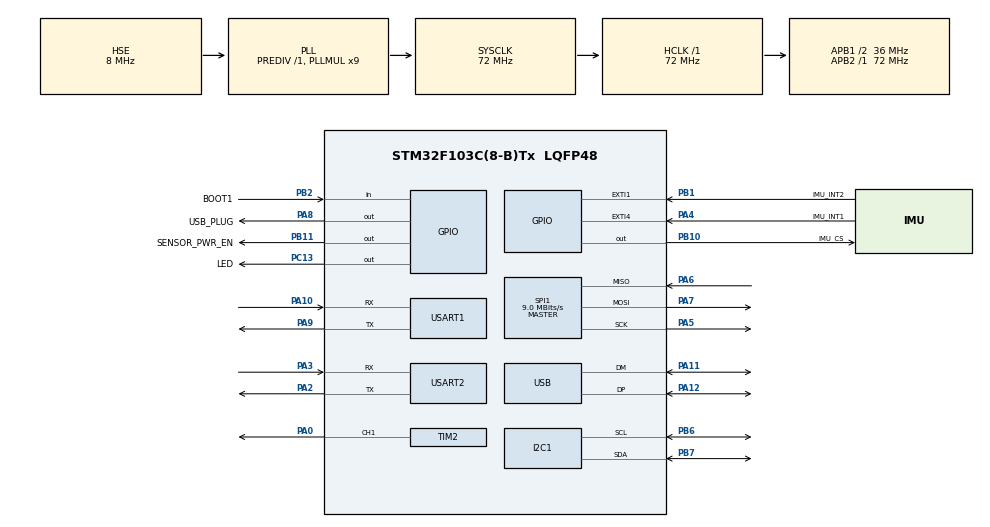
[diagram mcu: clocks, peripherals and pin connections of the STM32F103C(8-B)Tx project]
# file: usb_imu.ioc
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Mcu.Family=STM32F1
Mcu.Name=STM32F103C(8-B)Tx
Mcu.Package=LQFP48
NVIC.PriorityGroup=NVIC_PRIORITYGROUP_4
NVIC.TIM4_IRQn=true\:15\:0\:false\:false\:true\:false\:true\:true
NVIC.TimeBase=TIM4_IRQn
NVIC.TimeBaseIP=TIM4
NVIC.USB_LP_CAN1_RX0_IRQn=true\:0\:0\:false\:false\:true\:false\:true\:true
PA0-WKUP.Signal=S_TIM2_CH1_ETR
PA10.Mode=Asynchronous
PA10.Signal=USART1_RX
PA11.Mode=Device
PA11.Signal=USB_DM
PA12.Mode=Device
PA12.Signal=USB_DP
PA13.Mode=Serial_Wire
PA13.Signal=SYS_JTMS-SWDIO
PA14.Mode=Serial_Wire
PA14.Signal=SYS_JTCK-SWCLK
PA2.Mode=Asynchronous
PA2.Signal=USART2_TX
PA3.Mode=Asynchronous
PA3.Signal=USART2_RX
PA4.GPIO_Label=IMU_INT1
PA4.Signal=GPXTI4
PA5.Mode=Full_Duplex_Master
PA5.Signal=SPI1_SCK
PA6.Mode=Full_Duplex_Master
PA6.Signal=SPI1_MISO
PA7.Mode=Full_Duplex_Master
PA7.Signal=SPI1_MOSI
PA8.GPIO_Label=USB_PLUG
PA8.Signal=GPIO_Output
PA9.Mode=Asynchronous
PA9.Signal=USART1_TX
PB1.GPIO_Label=IMU_INT2
PB1.Signal=GPXTI1
PB10.GPIO_Label=IMU_CS
PB10.Signal=GPIO_Output
PB11.GPIO_Label=SENSOR_PWR_EN
PB11.Signal=GPIO_Output
PB2.GPIO_Label=BOOT1
PB2.Signal=GPIO_Input
PB6.Mode=I2C
PB6.Signal=I2C1_SCL
PB7.Mode=I2C
PB7.Signal=I2C1_SDA
PC13-TAMPER-RTC.GPIO_Label=LED
PC13-TAMPER-RTC.Signal=GPIO_Output
PD0-OSC_IN.Mode=HSE-External-Oscillator
PD0-OSC_IN.Signal=RCC_OSC_IN
PD1-OSC_OUT.Mode=HSE-External-Oscillator
PD1-OSC_OUT.Signal=RCC_OSC_OUT
ProjectManager.HeapSize=0x200
ProjectManager.StackSize=0x400
ProjectManager.TargetToolchain=Makefile
RCC.AHBFreq_Value=72000000
RCC.APB1CLKDivider=RCC_HCLK_DIV2
RCC.APB1Freq_Value=36000000
RCC.APB1TimFreq_Value=72000000
RCC.APB2Freq_Value=72000000
RCC.APB2TimFreq_Value=72000000
RCC.HCLKFreq_Value=72000000
RCC.PLLMUL=RCC_PLL_MUL9
RCC.SYSCLKFreq_VALUE=72000000
RCC.SYSCLKSource=RCC_SYSCLKSOURCE_PLLCLK
RCC.USBFreq_Value=48000000
RCC.USBPrescaler=RCC_USBCLKSOURCE_PLL_DIV1_5
SH.S_TIM2_CH1_ETR.0=TIM2_CH1,PWM Generation1 CH1
SPI1.BaudRatePrescaler=SPI_BAUDRATEPRESCALER_8
SPI1.CalculateBaudRate=9.0 MBits/s
SPI1.Direction=SPI_DIRECTION_2LINES
SPI1.Mode=SPI_MODE_MASTER
SPI1.VirtualType=VM_MASTER
TIM2.Channel-PWM\ Generation1\ CH1=TIM_CHANNEL_1
USART1.VirtualMode=VM_ASYNC
USART2.VirtualMode=VM_ASYNC
USB_DEVICE.CLASS_NAME_FS=CDC
USB_DEVICE.VirtualMode=Cdc
USB_DEVICE.VirtualModeFS=Cdc_FS
VP_CRC_VS_CRC.Mode=CRC_Activate
VP_SYS_VS_tim4.Mode=TIM4
VP_TIM2_VS_ClockSourceINT.Mode=Internal
VP_USB_DEVICE_VS_USB_DEVICE_CDC_FS.Mode=CDC_FS
board=custom

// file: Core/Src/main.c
/* USER CODE BEGIN Header */
/**
  ******************************************************************************
  * @file           : main.c
  * @brief          : Main program body
  ******************************************************************************
  * @attention
  *
  * Copyright (c) 2025 STMicroelectronics.
  * All rights reserved.
  *
  * This software is licensed under terms that can be found in the LICENSE file
  * in the root directory of this software component.
  * If no LICENSE file comes with this software, it is provided AS-IS.
  *
  ******************************************************************************
  */
/* USER CODE END Header */
#include "main.h"
#include "crc.h"
#include "i2c.h"
#include "spi.h"
#include "tim.h"
#include "usart.h"
#include "usb_device.h"
#include "gpio.h"

/* USER CODE BEGIN Includes */
#include "cpp_entry.hpp"
/* USER CODE END Includes */

void SystemClock_Config(void);

int main(void)
{

  /* MCU Configuration--------------------------------------------------------*/

  /* Reset of all peripherals, Initializes the Flash interface and the Systick. */
  HAL_Init();

  /* Configure the system clock */
  SystemClock_Config();

  /* Initialize all configured peripherals */
  MX_GPIO_Init();
  MX_CRC_Init();
  MX_USB_DEVICE_Init();
  MX_I2C1_Init();
  MX_SPI1_Init();
  MX_TIM2_Init();
  MX_USART1_UART_Init();
  MX_USART2_UART_Init();
  /* USER CODE BEGIN 2 */
  setup();
  loop();
  /* USER CODE END 2 */

  /* Infinite loop */
  while (1)
  {

  }
}

void SystemClock_Config(void)
{
  RCC_OscInitTypeDef RCC_OscInitStruct = {0};
  RCC_ClkInitTypeDef RCC_ClkInitStruct = {0};
  RCC_PeriphCLKInitTypeDef PeriphClkInit = {0};

  /** Initializes the RCC Oscillators according to the specified parameters
  * in the RCC_OscInitTypeDef structure.
  */
  RCC_OscInitStruct.OscillatorType = RCC_OSCILLATORTYPE_HSE;
  RCC_OscInitStruct.HSEState = RCC_HSE_ON;
  RCC_OscInitStruct.HSEPredivValue = RCC_HSE_PREDIV_DIV1;
  RCC_OscInitStruct.HSIState = RCC_HSI_ON;
  RCC_OscInitStruct.PLL.PLLState = RCC_PLL_ON;
  RCC_OscInitStruct.PLL.PLLSource = RCC_PLLSOURCE_HSE;
  RCC_OscInitStruct.PLL.PLLMUL = RCC_PLL_MUL9;
  if (HAL_RCC_OscConfig(&RCC_OscInitStruct) != HAL_OK)
  {
    Error_Handler();
  }

  /** Initializes the CPU, AHB and APB buses clocks
  */
  RCC_ClkInitStruct.ClockType = RCC_CLOCKTYPE_HCLK|RCC_CLOCKTYPE_SYSCLK
                              |RCC_CLOCKTYPE_PCLK1|RCC_CLOCKTYPE_PCLK2;
  RCC_ClkInitStruct.SYSCLKSource = RCC_SYSCLKSOURCE_PLLCLK;
  RCC_ClkInitStruct.AHBCLKDivider = RCC_SYSCLK_DIV1;
  RCC_ClkInitStruct.APB1CLKDivider = RCC_HCLK_DIV2;
  RCC_ClkInitStruct.APB2CLKDivider = RCC_HCLK_DIV1;

  if (HAL_RCC_ClockConfig(&RCC_ClkInitStruct, FLASH_LATENCY_2) != HAL_OK)
  {
    Error_Handler();
  }
  PeriphClkInit.PeriphClockSelection = RCC_PERIPHCLK_USB;
  PeriphClkInit.UsbClockSelection = RCC_USBCLKSOURCE_PLL_DIV1_5;
  if (HAL_RCCEx_PeriphCLKConfig(&PeriphClkInit) != HAL_OK)
  {
    Error_Handler();
  }
}

void HAL_TIM_PeriodElapsedCallback(TIM_HandleTypeDef *htim)
{
  if (htim->Instance == TIM4) {
    HAL_IncTick();
  }
}

void Error_Handler(void)
{
  __disable_irq();
  while (1)
  {
  }
}
